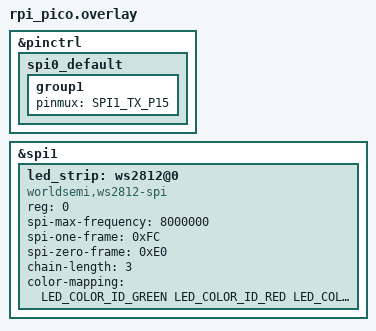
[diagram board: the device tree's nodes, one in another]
#include <dt-bindings/led/led.h>
#include <dt-bindings/pinctrl/rpi-pico-rp2040-pinctrl.h>

&pinctrl {
    spi0_default: spi0_default {
        group1 {
            pinmux = <SPI1_TX_P15>;
        };
    };
};

&spi1 {

  led_strip: ws2812@0{
    compatible = "worldsemi,ws2812-spi";

    /* SPI */
    reg = <0>;
    spi-max-frequency = <8000000>;
    spi-one-frame = <0xFC>;
    spi-zero-frame = <0xE0>;

    /* WS2812 */
    chain-length = <3>; /* number of LEDs */
    // spi-one-frame = <0x70>; /* make sure to configure this properly for your SOC */
    // spi-zero-frame = <0x40>; /* make sure to configure this properly for your SOC */
    color-mapping = <LED_COLOR_ID_GREEN
                          LED_COLOR_ID_RED
                          LED_COLOR_ID_BLUE>;
  };
};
